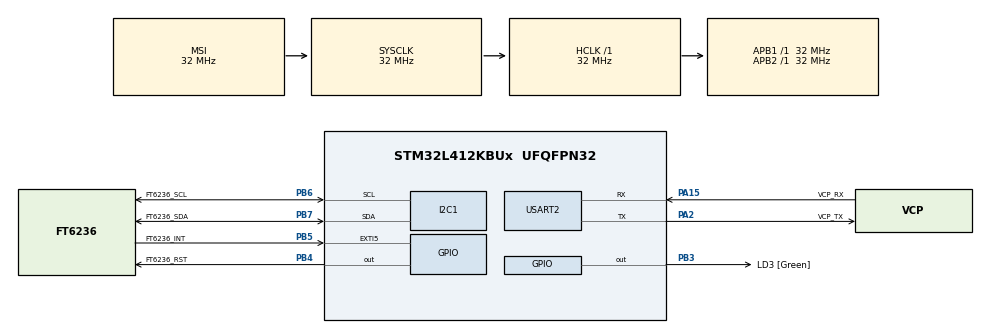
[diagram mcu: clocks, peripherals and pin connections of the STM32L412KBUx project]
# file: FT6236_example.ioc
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I2C1.Timing=0x00707CBB
Mcu.Family=STM32L4
Mcu.Name=STM32L412KBUx
Mcu.Package=UFQFPN32
NVIC.EXTI9_5_IRQn=true\:0\:0\:false\:false\:true\:true\:true\:true
NVIC.PriorityGroup=NVIC_PRIORITYGROUP_4
PA0-CK_IN.Mode=HSE-External-Clock-Source-for-LittleOrca
PA0-CK_IN.Signal=RCC_CK_IN
PA13\ (JTMS/SWDIO).GPIO_Label=SWDIO
PA13\ (JTMS/SWDIO).Mode=Serial_Wire
PA13\ (JTMS/SWDIO).Signal=SYS_JTMS-SWDIO
PA14\ (JTCK/SWCLK).GPIO_Label=SWCLK
PA14\ (JTCK/SWCLK).Mode=Serial_Wire
PA14\ (JTCK/SWCLK).Signal=SYS_JTCK-SWCLK
PA15\ (JTDI).GPIO_Label=VCP_RX
PA15\ (JTDI).Mode=Asynchronous
PA15\ (JTDI).Signal=USART2_RX
PA2.GPIO_Label=VCP_TX
PA2.Mode=Asynchronous
PA2.Signal=USART2_TX
PB3\ (JTDO/TRACESWO).GPIO_Label=LD3 [Green]
PB3\ (JTDO/TRACESWO).Signal=GPIO_Output
PB4\ (NJTRST).GPIO_Label=FT6236_RST
PB4\ (NJTRST).GPIO_PuPd=GPIO_PULLUP
PB4\ (NJTRST).PinState=GPIO_PIN_SET
PB4\ (NJTRST).Signal=GPIO_Output
PB5.GPIO_Label=FT6236_INT
PB5.GPIO_ModeDefaultEXTI=GPIO_MODE_IT_FALLING
PB5.Signal=GPXTI5
PB6.GPIO_FM6=SYSCFG_FASTMODEPLUS_PB6
PB6.GPIO_Label=FT6236_SCL
PB6.GPIO_Pu=GPIO_PULLUP
PB6.Mode=I2C
PB6.Signal=I2C1_SCL
PB7.GPIO_FM7=SYSCFG_FASTMODEPLUS_PB7
PB7.GPIO_Label=FT6236_SDA
PB7.GPIO_Pu=GPIO_PULLUP
PB7.Mode=I2C
PB7.Signal=I2C1_SDA
PC14-OSC32_IN\ (PC14).Mode=LSE-External-Oscillator
PC14-OSC32_IN\ (PC14).Signal=RCC_OSC32_IN
PC15-OSC32_OUT\ (PC15).Mode=LSE-External-Oscillator
PC15-OSC32_OUT\ (PC15).Signal=RCC_OSC32_OUT
ProjectManager.HeapSize=0x200
ProjectManager.StackSize=0x400
ProjectManager.TargetToolchain=STM32CubeIDE
RCC.ADCFreq_Value=32000000
RCC.AHBFreq_Value=32000000
RCC.APB1Freq_Value=32000000
RCC.APB1TimFreq_Value=32000000
RCC.APB2Freq_Value=32000000
RCC.APB2TimFreq_Value=32000000
RCC.CortexFreq_Value=32000000
RCC.FLatency=FLASH_LATENCY_1
RCC.HCLKFreq_Value=32000000
RCC.HSE_VALUE=8000000
RCC.HSI48_VALUE=48000000
RCC.HSICalibrationValue=16
RCC.HSI_VALUE=16000000
RCC.LSE_Drive_Capability=RCC_LSEDRIVE_LOW
RCC.MSIClockRange=RCC_MSIRANGE_10
RCC.MSI_VALUE=32000000
RCC.SYSCLKFreq_VALUE=32000000
RCC.USBFreq_Value=32000000
RCC.VCOOutputFreq_Value=256000000
USART2.VirtualMode-Asynchronous=VM_ASYNC
board=NUCLEO-L412KB

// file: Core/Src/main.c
/* USER CODE BEGIN Header */
/**
  ******************************************************************************
  * @file           : main.c
  * @brief          : Main program body
  ******************************************************************************
  * @attention
  *
  * Copyright (c) 2023 STMicroelectronics.
  * All rights reserved.
  *
  * This software is licensed under terms that can be found in the LICENSE file
  * in the root directory of this software component.
  * If no LICENSE file comes with this software, it is provided AS-IS.
  *
  ******************************************************************************
  */
/* USER CODE END Header */
#include "main.h"
#include "i2c.h"
#include "usart.h"
#include "gpio.h"

void SystemClock_Config(void);

int main(void)
{
  /* USER CODE BEGIN 1 */
	st_ft6236 *pst_ft6236 = &gst_ft6236;
  /* USER CODE END 1 */

  /* MCU Configuration--------------------------------------------------------*/

  /* Reset of all peripherals, Initializes the Flash interface and the Systick. */
  HAL_Init();

  /* Configure the system clock */
  SystemClock_Config();

  /* Initialize all configured peripherals */
  MX_GPIO_Init();
  MX_USART2_UART_Init();
  MX_I2C1_Init();
  /* USER CODE BEGIN 2 */

  // Init FT6236
  if( ft6236_init( ) != FT_ERROR )
  {
	  // Error handling
  }

  /* USER CODE END 2 */

  /* Infinite loop */
  /* USER CODE BEGIN WHILE */
  while (1)
  {
	  // Check if screen was pressed
	  if( pst_ft6236->ok )
	  {
		  ft6236_read( );
	  }

	  // Add small delay helps with multiple detection
	  HAL_Delay(10);
    /* USER CODE END WHILE */

  }
}

void SystemClock_Config(void)
{
  RCC_OscInitTypeDef RCC_OscInitStruct = {0};
  RCC_ClkInitTypeDef RCC_ClkInitStruct = {0};

  /** Configure the main internal regulator output voltage
  */
  if (HAL_PWREx_ControlVoltageScaling(PWR_REGULATOR_VOLTAGE_SCALE1) != HAL_OK)
  {
    Error_Handler();
  }

  /** Configure LSE Drive Capability
  */
  HAL_PWR_EnableBkUpAccess();
  __HAL_RCC_LSEDRIVE_CONFIG(RCC_LSEDRIVE_LOW);

  /** Initializes the RCC Oscillators according to the specified parameters
  * in the RCC_OscInitTypeDef structure.
  */
  RCC_OscInitStruct.OscillatorType = RCC_OSCILLATORTYPE_LSE|RCC_OSCILLATORTYPE_MSI;
  RCC_OscInitStruct.LSEState = RCC_LSE_ON;
  RCC_OscInitStruct.MSIState = RCC_MSI_ON;
  RCC_OscInitStruct.MSICalibrationValue = 0;
  RCC_OscInitStruct.MSIClockRange = RCC_MSIRANGE_10;
  RCC_OscInitStruct.PLL.PLLState = RCC_PLL_NONE;
  if (HAL_RCC_OscConfig(&RCC_OscInitStruct) != HAL_OK)
  {
    Error_Handler();
  }

  /** Initializes the CPU, AHB and APB buses clocks
  */
  RCC_ClkInitStruct.ClockType = RCC_CLOCKTYPE_HCLK|RCC_CLOCKTYPE_SYSCLK
                              |RCC_CLOCKTYPE_PCLK1|RCC_CLOCKTYPE_PCLK2;
  RCC_ClkInitStruct.SYSCLKSource = RCC_SYSCLKSOURCE_MSI;
  RCC_ClkInitStruct.AHBCLKDivider = RCC_SYSCLK_DIV1;
  RCC_ClkInitStruct.APB1CLKDivider = RCC_HCLK_DIV1;
  RCC_ClkInitStruct.APB2CLKDivider = RCC_HCLK_DIV1;

  if (HAL_RCC_ClockConfig(&RCC_ClkInitStruct, FLASH_LATENCY_1) != HAL_OK)
  {
    Error_Handler();
  }

  /** Enable MSI Auto calibration
  */
  HAL_RCCEx_EnableMSIPLLMode();
}

void Error_Handler(void)
{
  __disable_irq();
  while (1)
  {
  }
}
